AUTOSAR XML (schema 4-0-3)
standard types defined: UInt16
package /AUTOSAR_Platform/DataConstrs
  range DC_UInt16: raw 0..65535
package /PATAC/EEPROM/BaseType
  base type PJB_UInt16: category=FIXED_LENGTH, base-type-size=16, base-type-encoding=NONE, native-declaration=unsigned short
package /PATAC/EEPROM/ImplementationDataType
  impl type EEP_Uint16: category=VALUE, base-type=PJB_UInt16, sw-calibration-access=READ-ONLY, type-emitter=RTE
package /PATAC/MSM/ComponentTypes
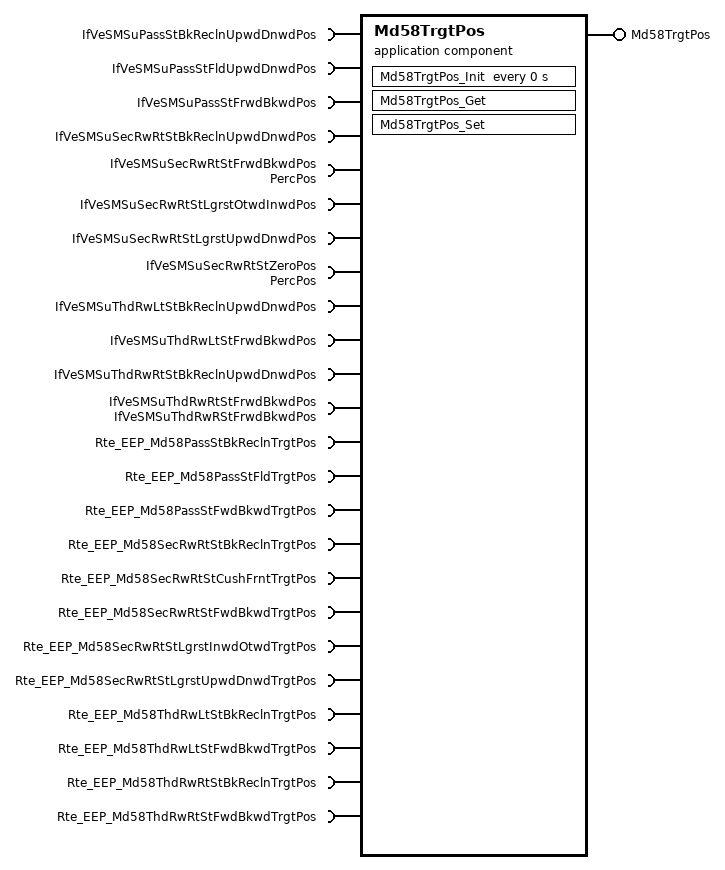
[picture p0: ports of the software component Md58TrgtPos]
  application sw component type Md58TrgtPos
    provide port Md58TrgtPos: provided-com-specs=[{operation=Md58TrgtPos/Get, queue-length=1}, {operation=Md58TrgtPos/Set, queue-length=1}], provided-interface=Md58TrgtPos
    24 x require port:
      IfVeSMSuPassStBkReclnUpwdDnwdPos: nonqueued-receiver-com-spec{data-element=IfVeSMSuPassStBkReclnUpwdDnwdPos/Val, filter=data-filter-type=ALWAYS, init-value=0}, required-interface=IfVeSMSuPassStBkReclnUpwdDnwdPos
      IfVeSMSuPassStFldUpwdDnwdPos: nonqueued-receiver-com-spec{data-element=IfVeSMSuPassStFldUpwdDnwdPos/Val, filter=data-filter-type=ALWAYS, init-value=0}, required-interface=IfVeSMSuPassStFldUpwdDnwdPos
      IfVeSMSuPassStFrwdBkwdPos: nonqueued-receiver-com-spec{data-element=IfVeSMSuPassStFrwdBkwdPos/Val, filter=data-filter-type=ALWAYS, init-value=0}, required-interface=IfVeSMSuPassStFrwdBkwdPos
      IfVeSMSuSecRwRtStBkReclnUpwdDnwdPos: nonqueued-receiver-com-spec{data-element=IfVeSMSuSecRwRtStBkReclnUpwdDnwdPos/Val, filter=data-filter-type=ALWAYS, init-value=0}, required-interface=IfVeSMSuSecRwRtStBkReclnUpwdDnwdPos
      IfVeSMSuSecRwRtStFrwdBkwdPos: nonqueued-receiver-com-spec{data-element=PercPos/Val, filter=data-filter-type=ALWAYS, init-value=0}, required-interface=PercPos
      IfVeSMSuSecRwRtStLgrstOtwdInwdPos: nonqueued-receiver-com-spec{data-element=IfVeSMSuSecRwRtStLgrstOtwdInwdPos/Val, filter=data-filter-type=ALWAYS, init-value=0}, required-interface=IfVeSMSuSecRwRtStLgrstOtwdInwdPos
      IfVeSMSuSecRwRtStLgrstUpwdDnwdPos: nonqueued-receiver-com-spec{data-element=IfVeSMSuSecRwRtStLgrstUpwdDnwdPos/Val, filter=data-filter-type=ALWAYS, init-value=0}, required-interface=IfVeSMSuSecRwRtStLgrstUpwdDnwdPos
      IfVeSMSuSecRwRtStZeroPos: nonqueued-receiver-com-spec{data-element=PercPos/Val, filter=data-filter-type=ALWAYS, init-value=0}, required-interface=PercPos
      IfVeSMSuThdRwLtStBkReclnUpwdDnwdPos: nonqueued-receiver-com-spec{data-element=IfVeSMSuThdRwLtStBkReclnUpwdDnwdPos/Val, filter=data-filter-type=ALWAYS, init-value=0}, required-interface=IfVeSMSuThdRwLtStBkReclnUpwdDnwdPos
      IfVeSMSuThdRwLtStFrwdBkwdPos: nonqueued-receiver-com-spec{data-element=IfVeSMSuThdRwLtStFrwdBkwdPos/Val, filter=data-filter-type=ALWAYS, init-value=0}, required-interface=IfVeSMSuThdRwLtStFrwdBkwdPos
      IfVeSMSuThdRwRtStBkReclnUpwdDnwdPos: nonqueued-receiver-com-spec{data-element=IfVeSMSuThdRwRtStBkReclnUpwdDnwdPos/Val, filter=data-filter-type=ALWAYS, init-value=0}, required-interface=IfVeSMSuThdRwRtStBkReclnUpwdDnwdPos
      IfVeSMSuThdRwRtStFrwdBkwdPos: nonqueued-receiver-com-spec{data-element=IfVeSMSuThdRwRStFrwdBkwdPos/Val, filter=data-filter-type=ALWAYS, init-value=0}, required-interface=IfVeSMSuThdRwRStFrwdBkwdPos
      Rte_EEP_Md58PassStBkReclnTrgtPos: required-com-specs=[Rte_EEP_Md58PassStBkReclnTrgtPos/Get, Rte_EEP_Md58PassStBkReclnTrgtPos/Set], required-interface=Rte_EEP_Md58PassStBkReclnTrgtPos
      Rte_EEP_Md58PassStFldTrgtPos: required-com-specs=[Rte_EEP_Md58PassStFldTrgtPos/Get, Rte_EEP_Md58PassStFldTrgtPos/Set], required-interface=Rte_EEP_Md58PassStFldTrgtPos
      Rte_EEP_Md58PassStFwdBkwdTrgtPos: required-com-specs=[Rte_EEP_Md58PassStFwdBkwdTrgtPos/Get, Rte_EEP_Md58PassStFwdBkwdTrgtPos/Set], required-interface=Rte_EEP_Md58PassStFwdBkwdTrgtPos
      Rte_EEP_Md58SecRwRtStBkReclnTrgtPos: required-com-specs=[Rte_EEP_Md58SecRwRtStBkReclnTrgtPos/Get, Rte_EEP_Md58SecRwRtStBkReclnTrgtPos/Set], required-interface=Rte_EEP_Md58SecRwRtStBkReclnTrgtPos
      Rte_EEP_Md58SecRwRtStCushFrntTrgtPos: required-com-specs=[Rte_EEP_Md58SecRwRtStCushFrntTrgtPos/Get, Rte_EEP_Md58SecRwRtStCushFrntTrgtPos/Set], required-interface=Rte_EEP_Md58SecRwRtStCushFrntTrgtPos
      Rte_EEP_Md58SecRwRtStFwdBkwdTrgtPos: required-com-specs=[Rte_EEP_Md58SecRwRtStFwdBkwdTrgtPos/Get, Rte_EEP_Md58SecRwRtStFwdBkwdTrgtPos/Set], required-interface=Rte_EEP_Md58SecRwRtStFwdBkwdTrgtPos
      Rte_EEP_Md58SecRwRtStLgrstInwdOtwdTrgtPos: required-com-specs=[Rte_EEP_Md58SecRwRtStLgrstInwdOtwdTrgtPos/Get, Rte_EEP_Md58SecRwRtStLgrstInwdOtwdTrgtPos/Set], required-interface=Rte_EEP_Md58SecRwRtStLgrstInwdOtwdTrgtPos
      Rte_EEP_Md58SecRwRtStLgrstUpwdDnwdTrgtPos: required-com-specs=[Rte_EEP_Md58SecRwRtStLgrstUpwdDnwdTrgtPos/Get, Rte_EEP_Md58SecRwRtStLgrstUpwdDnwdTrgtPos/Set], required-interface=Rte_EEP_Md58SecRwRtStLgrstUpwdDnwdTrgtPos
      Rte_EEP_Md58ThdRwLtStBkReclnTrgtPos: required-com-specs=[Rte_EEP_Md58ThdRwLtStBkReclnTrgtPos/Get, Rte_EEP_Md58ThdRwLtStBkReclnTrgtPos/Set], required-interface=Rte_EEP_Md58ThdRwLtStBkReclnTrgtPos
      Rte_EEP_Md58ThdRwLtStFwdBkwdTrgtPos: required-com-specs=[Rte_EEP_Md58ThdRwLtStFwdBkwdTrgtPos/Get, Rte_EEP_Md58ThdRwLtStFwdBkwdTrgtPos/Set], required-interface=Rte_EEP_Md58ThdRwLtStFwdBkwdTrgtPos
      Rte_EEP_Md58ThdRwRtStBkReclnTrgtPos: required-com-specs=[Rte_EEP_Md58ThdRwRtStBkReclnTrgtPos/Get, Rte_EEP_Md58ThdRwRtStBkReclnTrgtPos/Set], required-interface=Rte_EEP_Md58ThdRwRtStBkReclnTrgtPos
      Rte_EEP_Md58ThdRwRtStFwdBkwdTrgtPos: required-com-specs=[Rte_EEP_Md58ThdRwRtStFwdBkwdTrgtPos/Get, Rte_EEP_Md58ThdRwRtStFwdBkwdTrgtPos/Set], required-interface=Rte_EEP_Md58ThdRwRtStFwdBkwdTrgtPos
    behavior Md58TrgtPos_InternalBehavior
      operation invoked event OIT_Md58TrgtPos_Get_Md58TrgtPos_Get: start-on-event=Md58TrgtPos_Get, operation=Md58TrgtPos.Get
      timing event Md58TrgtPos_InitEvent: start-on-event=Md58TrgtPos_Init, period=0
      operation invoked event OIT_Md58TrgtPos_Set_Md58TrgtPos_Set: start-on-event=Md58TrgtPos_Set, operation=Md58TrgtPos.Set
      runnable Md58TrgtPos_Get
        12 x sync call, all with timeout=0:
          SC_Rte_EEP_Md58PassStBkReclnTrgtPos_Get: operation=Rte_EEP_Md58PassStBkReclnTrgtPos.Get
          SC_Rte_EEP_Md58PassStFldTrgtPos_Get: operation=Rte_EEP_Md58PassStFldTrgtPos.Get
          SC_Rte_EEP_Md58PassStFwdBkwdTrgtPos_Get: operation=Rte_EEP_Md58PassStFwdBkwdTrgtPos.Get
          SC_Rte_EEP_Md58SecRwRtStBkReclnTrgtPos_Get: operation=Rte_EEP_Md58SecRwRtStBkReclnTrgtPos.Get
          SC_Rte_EEP_Md58SecRwRtStCushFrntTrgtPos_Get: operation=Rte_EEP_Md58SecRwRtStCushFrntTrgtPos.Get
          SC_Rte_EEP_Md58SecRwRtStFwdBkwdTrgtPos_Get: operation=Rte_EEP_Md58SecRwRtStFwdBkwdTrgtPos.Get
          SC_Rte_EEP_Md58SecRwRtStLgrstInwdOtwdTrgtPos_Get: operation=Rte_EEP_Md58SecRwRtStLgrstInwdOtwdTrgtPos.Get
          SC_Rte_EEP_Md58SecRwRtStLgrstUpwdDnwdTrgtPos_Get: operation=Rte_EEP_Md58SecRwRtStLgrstUpwdDnwdTrgtPos.Get
          SC_Rte_EEP_Md58ThdRwLtStBkReclnTrgtPos_Get: operation=Rte_EEP_Md58ThdRwLtStBkReclnTrgtPos.Get
          SC_Rte_EEP_Md58ThdRwLtStFwdBkwdTrgtPos_Get: operation=Rte_EEP_Md58ThdRwLtStFwdBkwdTrgtPos.Get
          SC_Rte_EEP_Md58ThdRwRtStBkReclnTrgtPos_Get: operation=Rte_EEP_Md58ThdRwRtStBkReclnTrgtPos.Get
          SC_Rte_EEP_Md58ThdRwRtStFwdBkwdTrgtPos_Get: operation=Rte_EEP_Md58ThdRwRtStFwdBkwdTrgtPos.Get
      runnable Md58TrgtPos_Init
      runnable Md58TrgtPos_Set
        data-receive-point-by-arguments:
          12 x access:
            REC_IfVeSMSuPassStBkReclnUpwdDnwdPos_Val: accessed-variable=IfVeSMSuPassStBkReclnUpwdDnwdPos.Val
            REC_IfVeSMSuPassStFldUpwdDnwdPos_Val: accessed-variable=IfVeSMSuPassStFldUpwdDnwdPos.Val
            REC_IfVeSMSuPassStFrwdBkwdPos_Val: accessed-variable=IfVeSMSuPassStFrwdBkwdPos.Val
            REC_IfVeSMSuSecRwRtStBkReclnUpwdDnwdPos_Val: accessed-variable=IfVeSMSuSecRwRtStBkReclnUpwdDnwdPos.Val
            REC_IfVeSMSuSecRwRtStFrwdBkwdPos_Val: accessed-variable=IfVeSMSuSecRwRtStFrwdBkwdPos.Val
            REC_IfVeSMSuSecRwRtStLgrstOtwdInwdPos_Val: accessed-variable=IfVeSMSuSecRwRtStLgrstOtwdInwdPos.Val
            REC_IfVeSMSuSecRwRtStLgrstUpwdDnwdPos_Val: accessed-variable=IfVeSMSuSecRwRtStLgrstUpwdDnwdPos.Val
            REC_IfVeSMSuSecRwRtStZeroPos_Val: accessed-variable=IfVeSMSuSecRwRtStZeroPos.Val
            REC_IfVeSMSuThdRwLtStBkReclnUpwdDnwdPos_Val: accessed-variable=IfVeSMSuThdRwLtStBkReclnUpwdDnwdPos.Val
            REC_IfVeSMSuThdRwLtStFrwdBkwdPos_Val: accessed-variable=IfVeSMSuThdRwLtStFrwdBkwdPos.Val
            REC_IfVeSMSuThdRwRtStBkReclnUpwdDnwdPos_Val: accessed-variable=IfVeSMSuThdRwRtStBkReclnUpwdDnwdPos.Val
            REC_IfVeSMSuThdRwRtStFrwdBkwdPos_Val: accessed-variable=IfVeSMSuThdRwRtStFrwdBkwdPos.Val
        12 x sync call, all with timeout=0:
          SC_Rte_EEP_Md58PassStBkReclnTrgtPos_Set: operation=Rte_EEP_Md58PassStBkReclnTrgtPos.Set
          SC_Rte_EEP_Md58PassStFldTrgtPos_Set: operation=Rte_EEP_Md58PassStFldTrgtPos.Set
          SC_Rte_EEP_Md58PassStFwdBkwdTrgtPos_Set: operation=Rte_EEP_Md58PassStFwdBkwdTrgtPos.Set
          SC_Rte_EEP_Md58SecRwRtStBkReclnTrgtPos_Set: operation=Rte_EEP_Md58SecRwRtStBkReclnTrgtPos.Set
          SC_Rte_EEP_Md58SecRwRtStCushFrntTrgtPos_Set: operation=Rte_EEP_Md58SecRwRtStCushFrntTrgtPos.Set
          SC_Rte_EEP_Md58SecRwRtStFwdBkwdTrgtPos_Set: operation=Rte_EEP_Md58SecRwRtStFwdBkwdTrgtPos.Set
          SC_Rte_EEP_Md58SecRwRtStLgrstInwdOtwdTrgtPos_Set: operation=Rte_EEP_Md58SecRwRtStLgrstInwdOtwdTrgtPos.Set
          SC_Rte_EEP_Md58SecRwRtStLgrstUpwdDnwdTrgtPos_Set: operation=Rte_EEP_Md58SecRwRtStLgrstUpwdDnwdTrgtPos.Set
          SC_Rte_EEP_Md58ThdRwLtStBkReclnTrgtPos_Set: operation=Rte_EEP_Md58ThdRwLtStBkReclnTrgtPos.Set
          SC_Rte_EEP_Md58ThdRwLtStFwdBkwdTrgtPos_Set: operation=Rte_EEP_Md58ThdRwLtStFwdBkwdTrgtPos.Set
          SC_Rte_EEP_Md58ThdRwRtStBkReclnTrgtPos_Set: operation=Rte_EEP_Md58ThdRwRtStBkReclnTrgtPos.Set
          SC_Rte_EEP_Md58ThdRwRtStFwdBkwdTrgtPos_Set: operation=Rte_EEP_Md58ThdRwRtStFwdBkwdTrgtPos.Set
  swc implementation Md58TrgtPos_Implementation: behavior=Md58TrgtPos_InternalBehavior
    code-descriptors:
      code Default: artifact-descriptors=autosar-engineering-object={short-label=Default, category=SWSRC}
package /PATAC/MSM/ModeAdjust/PortInterface
  client server interface Md58TrgtPos
    operation Get
      12 x arg, all with type=UInt16, direction=OUT, server-argument-impl-policy=USE-ARGUMENT-TYPE:
        SecRwRtStBkReclnTrgtPos
        SecRwRtStZeroTrgtPos
        SecRwRtStLgrstUpwdDnwdTrgtPos
        SecRwRtStLgrstInwdOtwdTrgtPos
        ThdRwLtStBkReclnTrgtPos
        ThdRwLtStFwdBkwdTrgtPos
        ThdRwRtStBkReclnTrgtPos
        ThdRwRtStFwdBkwdTrgtPos
        PassStBkReclnTrgtPos
        PassStFwdBkwdTrgtPos
        SecRwRtStFwdBkwdTrgtPos
        PassStFldTrgtPos
    operation Set
  sender receiver interface IfVeSMSuPassStFldUpwdDnwdPos: invalidation-policy{data-element=IfVeSMSuPassStFldUpwdDnwdPos/Val, handle-invalid=DONT-INVALIDATE}
    data Val: type=UInt16
  sender receiver interface PercPos: invalidation-policy{data-element=PercPos/Val, handle-invalid=DONT-INVALIDATE}
    data Val: type=UInt16
package /PATAC/MSM/PortInterfaces
  9 x sender receiver interface:
    IfVeSMSuPassStBkReclnUpwdDnwdPos: invalidation-policy{data-element=IfVeSMSuPassStBkReclnUpwdDnwdPos/Val, handle-invalid=DONT-INVALIDATE}
      data Val: type=UInt16
    IfVeSMSuPassStFrwdBkwdPos: invalidation-policy{data-element=IfVeSMSuPassStFrwdBkwdPos/Val, handle-invalid=DONT-INVALIDATE}
      data Val: type=UInt16
    IfVeSMSuSecRwRtStBkReclnUpwdDnwdPos: invalidation-policy{data-element=IfVeSMSuSecRwRtStBkReclnUpwdDnwdPos/Val, handle-invalid=DONT-INVALIDATE}
      data Val: type=UInt16
    IfVeSMSuSecRwRtStLgrstOtwdInwdPos: invalidation-policy{data-element=IfVeSMSuSecRwRtStLgrstOtwdInwdPos/Val, handle-invalid=DONT-INVALIDATE}
      data Val: type=UInt16
    IfVeSMSuSecRwRtStLgrstUpwdDnwdPos: invalidation-policy{data-element=IfVeSMSuSecRwRtStLgrstUpwdDnwdPos/Val, handle-invalid=DONT-INVALIDATE}
      data Val: type=UInt16
    IfVeSMSuThdRwLtStBkReclnUpwdDnwdPos: invalidation-policy{data-element=IfVeSMSuThdRwLtStBkReclnUpwdDnwdPos/Val, handle-invalid=DONT-INVALIDATE}
      data Val: type=UInt16
    IfVeSMSuThdRwLtStFrwdBkwdPos: invalidation-policy{data-element=IfVeSMSuThdRwLtStFrwdBkwdPos/Val, handle-invalid=DONT-INVALIDATE}
      data Val: type=UInt16
    IfVeSMSuThdRwRStFrwdBkwdPos: invalidation-policy{data-element=IfVeSMSuThdRwRStFrwdBkwdPos/Val, handle-invalid=DONT-INVALIDATE}
      data Val: type=UInt16
    IfVeSMSuThdRwRtStBkReclnUpwdDnwdPos: invalidation-policy{data-element=IfVeSMSuThdRwRtStBkReclnUpwdDnwdPos/Val, handle-invalid=DONT-INVALIDATE}
      data Val: type=UInt16
package /PortInterfaces
  12 x client server interface:
    Rte_EEP_Md58PassStBkReclnTrgtPos
      operation Get
        arg arg: type=EEP_Uint16, direction=OUT, server-argument-impl-policy=USE-ARGUMENT-TYPE
      operation Set
        arg arg: type=EEP_Uint16, direction=IN, server-argument-impl-policy=USE-ARGUMENT-TYPE
    Rte_EEP_Md58PassStFldTrgtPos
      operation Get
        arg arg: type=EEP_Uint16, direction=OUT, server-argument-impl-policy=USE-ARGUMENT-TYPE
      operation Set
        arg arg: type=EEP_Uint16, direction=IN, server-argument-impl-policy=USE-ARGUMENT-TYPE
    Rte_EEP_Md58PassStFwdBkwdTrgtPos
      operation Get
        arg arg: type=EEP_Uint16, direction=OUT, server-argument-impl-policy=USE-ARGUMENT-TYPE
      operation Set
        arg arg: type=EEP_Uint16, direction=IN, server-argument-impl-policy=USE-ARGUMENT-TYPE
    Rte_EEP_Md58SecRwRtStBkReclnTrgtPos
      operation Get
        arg arg: type=EEP_Uint16, direction=OUT, server-argument-impl-policy=USE-ARGUMENT-TYPE
      operation Set
        arg arg: type=EEP_Uint16, direction=IN, server-argument-impl-policy=USE-ARGUMENT-TYPE
    Rte_EEP_Md58SecRwRtStCushFrntTrgtPos
      operation Get
        arg arg: type=EEP_Uint16, direction=OUT, server-argument-impl-policy=USE-ARGUMENT-TYPE
      operation Set
        arg arg: type=EEP_Uint16, direction=IN, server-argument-impl-policy=USE-ARGUMENT-TYPE
    Rte_EEP_Md58SecRwRtStFwdBkwdTrgtPos
      operation Get
        arg arg: type=EEP_Uint16, direction=OUT, server-argument-impl-policy=USE-ARGUMENT-TYPE
      operation Set
        arg arg: type=EEP_Uint16, direction=IN, server-argument-impl-policy=USE-ARGUMENT-TYPE
    Rte_EEP_Md58SecRwRtStLgrstInwdOtwdTrgtPos
      operation Get
        arg arg: type=EEP_Uint16, direction=OUT, server-argument-impl-policy=USE-ARGUMENT-TYPE
      operation Set
        arg arg: type=EEP_Uint16, direction=IN, server-argument-impl-policy=USE-ARGUMENT-TYPE
    Rte_EEP_Md58SecRwRtStLgrstUpwdDnwdTrgtPos
      operation Get
        arg arg: type=EEP_Uint16, direction=OUT, server-argument-impl-policy=USE-ARGUMENT-TYPE
      operation Set
        arg arg: type=EEP_Uint16, direction=IN, server-argument-impl-policy=USE-ARGUMENT-TYPE
    Rte_EEP_Md58ThdRwLtStBkReclnTrgtPos
      operation Get
        arg arg: type=EEP_Uint16, direction=OUT, server-argument-impl-policy=USE-ARGUMENT-TYPE
      operation Set
        arg arg: type=EEP_Uint16, direction=IN, server-argument-impl-policy=USE-ARGUMENT-TYPE
    Rte_EEP_Md58ThdRwLtStFwdBkwdTrgtPos
      operation Get
        arg arg: type=EEP_Uint16, direction=OUT, server-argument-impl-policy=USE-ARGUMENT-TYPE
      operation Set
        arg arg: type=EEP_Uint16, direction=IN, server-argument-impl-policy=USE-ARGUMENT-TYPE
    Rte_EEP_Md58ThdRwRtStBkReclnTrgtPos
      operation Get
        arg arg: type=EEP_Uint16, direction=OUT, server-argument-impl-policy=USE-ARGUMENT-TYPE
      operation Set
        arg arg: type=EEP_Uint16, direction=IN, server-argument-impl-policy=USE-ARGUMENT-TYPE
    Rte_EEP_Md58ThdRwRtStFwdBkwdTrgtPos
      operation Get
        arg arg: type=EEP_Uint16, direction=OUT, server-argument-impl-policy=USE-ARGUMENT-TYPE
      operation Set
        arg arg: type=EEP_Uint16, direction=IN, server-argument-impl-policy=USE-ARGUMENT-TYPE
